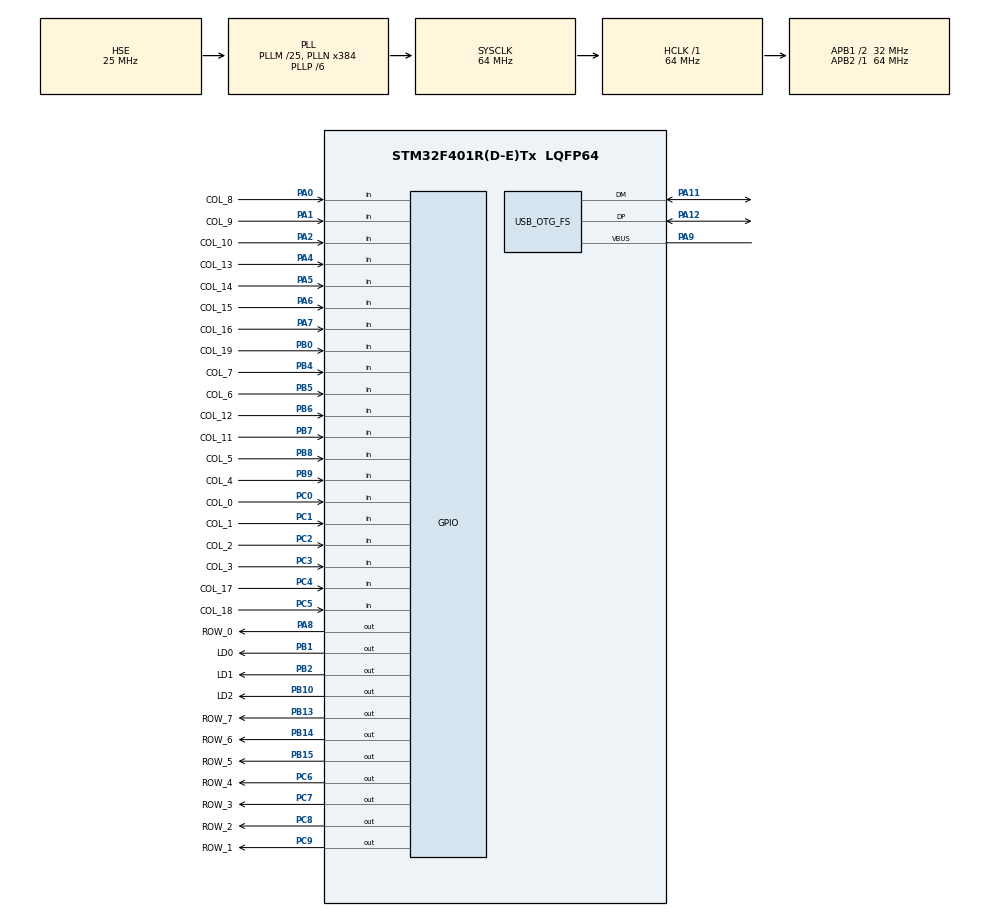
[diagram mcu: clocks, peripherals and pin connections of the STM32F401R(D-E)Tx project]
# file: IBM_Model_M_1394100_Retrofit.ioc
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FREERTOS.Tasks01=defaultTask,0,128,StartDefaultTask,Default,NULL,Dynamic,NULL,NULL
Mcu.Family=STM32F4
Mcu.Name=STM32F401R(D-E)Tx
Mcu.Package=LQFP64
NVIC.PriorityGroup=NVIC_PRIORITYGROUP_4
NVIC.TIM1_UP_TIM10_IRQn=true\:0\:0\:false\:false\:true\:false\:false\:true
NVIC.TimeBase=TIM1_UP_TIM10_IRQn
NVIC.TimeBaseIP=TIM10
PA0-WKUP.GPIO_Label=COL_8
PA0-WKUP.GPIO_Mode=GPIO_MODE_INPUT
PA0-WKUP.GPIO_PuPd=GPIO_PULLUP
PA0-WKUP.Signal=GPIO_Input
PA1.GPIO_Label=COL_9
PA1.GPIO_Mode=GPIO_MODE_INPUT
PA1.GPIO_PuPd=GPIO_PULLUP
PA1.Signal=GPIO_Input
PA11.Mode=Device_Only
PA11.Signal=USB_OTG_FS_DM
PA12.Mode=Device_Only
PA12.Signal=USB_OTG_FS_DP
PA13.Mode=Trace_Asynchronous_SW
PA13.Signal=SYS_JTMS-SWDIO
PA14.Mode=Trace_Asynchronous_SW
PA14.Signal=SYS_JTCK-SWCLK
PA2.GPIO_Label=COL_10
PA2.GPIO_Mode=GPIO_MODE_INPUT
PA2.GPIO_PuPd=GPIO_PULLUP
PA2.Signal=GPIO_Input
PA4.GPIO_Label=COL_13
PA4.GPIO_Mode=GPIO_MODE_INPUT
PA4.GPIO_PuPd=GPIO_PULLUP
PA4.Signal=GPIO_Input
PA5.GPIO_Label=COL_14
PA5.GPIO_Mode=GPIO_MODE_INPUT
PA5.GPIO_PuPd=GPIO_PULLUP
PA5.Signal=GPIO_Input
PA6.GPIO_Label=COL_15
PA6.GPIO_Mode=GPIO_MODE_INPUT
PA6.GPIO_PuPd=GPIO_PULLUP
PA6.Signal=GPIO_Input
PA7.GPIO_Label=COL_16
PA7.GPIO_Mode=GPIO_MODE_INPUT
PA7.GPIO_PuPd=GPIO_PULLUP
PA7.Signal=GPIO_Input
PA8.GPIO_Label=ROW_0
PA8.GPIO_ModeDefaultOutputPP=GPIO_MODE_OUTPUT_PP
PA8.GPIO_PuPd=GPIO_NOPULL
PA8.GPIO_Speed=GPIO_SPEED_FREQ_LOW
PA8.PinState=GPIO_PIN_SET
PA8.Signal=GPIO_Output
PA9.Mode=Activate_VBUS
PA9.Signal=USB_OTG_FS_VBUS
PB0.GPIO_Label=COL_19
PB0.GPIO_Mode=GPIO_MODE_INPUT
PB0.GPIO_PuPd=GPIO_PULLUP
PB0.Signal=GPIO_Input
PB1.GPIO_Label=LD0
PB1.Signal=GPIO_Output
PB10.GPIO_Label=LD2
PB10.Signal=GPIO_Output
PB13.GPIO_Label=ROW_7
PB13.GPIO_ModeDefaultOutputPP=GPIO_MODE_OUTPUT_PP
PB13.GPIO_PuPd=GPIO_NOPULL
PB13.GPIO_Speed=GPIO_SPEED_FREQ_LOW
PB13.PinState=GPIO_PIN_SET
PB13.Signal=GPIO_Output
PB14.GPIO_Label=ROW_6
PB14.GPIO_ModeDefaultOutputPP=GPIO_MODE_OUTPUT_PP
PB14.GPIO_PuPd=GPIO_NOPULL
PB14.GPIO_Speed=GPIO_SPEED_FREQ_LOW
PB14.PinState=GPIO_PIN_SET
PB14.Signal=GPIO_Output
PB15.GPIO_Label=ROW_5
PB15.GPIO_ModeDefaultOutputPP=GPIO_MODE_OUTPUT_PP
PB15.GPIO_PuPd=GPIO_NOPULL
PB15.GPIO_Speed=GPIO_SPEED_FREQ_LOW
PB15.PinState=GPIO_PIN_SET
PB15.Signal=GPIO_Output
PB2.GPIO_Label=LD1
PB2.Signal=GPIO_Output
PB3.Mode=Trace_Asynchronous_SW
PB3.Signal=SYS_JTDO-SWO
PB4.GPIO_Label=COL_7
PB4.GPIO_Mode=GPIO_MODE_INPUT
PB4.GPIO_PuPd=GPIO_PULLUP
PB4.Signal=GPIO_Input
PB5.GPIO_Label=COL_6
PB5.GPIO_Mode=GPIO_MODE_INPUT
PB5.GPIO_PuPd=GPIO_PULLUP
PB5.Signal=GPIO_Input
PB6.GPIO_Label=COL_12
PB6.GPIO_Mode=GPIO_MODE_INPUT
PB6.GPIO_PuPd=GPIO_PULLUP
PB6.Signal=GPIO_Input
PB7.GPIO_Label=COL_11
PB7.GPIO_Mode=GPIO_MODE_INPUT
PB7.GPIO_PuPd=GPIO_PULLUP
PB7.Signal=GPIO_Input
PB8.GPIO_Label=COL_5
PB8.GPIO_Mode=GPIO_MODE_INPUT
PB8.GPIO_PuPd=GPIO_PULLUP
PB8.Signal=GPIO_Input
PB9.GPIO_Label=COL_4
PB9.GPIO_Mode=GPIO_MODE_INPUT
PB9.GPIO_PuPd=GPIO_PULLUP
PB9.Signal=GPIO_Input
PC0.GPIO_Label=COL_0
PC0.GPIO_Mode=GPIO_MODE_INPUT
PC0.GPIO_PuPd=GPIO_PULLUP
PC0.Signal=GPIO_Input
PC1.GPIO_Label=COL_1
PC1.GPIO_Mode=GPIO_MODE_INPUT
PC1.GPIO_PuPd=GPIO_PULLUP
PC1.Signal=GPIO_Input
PC2.GPIO_Label=COL_2
PC2.GPIO_Mode=GPIO_MODE_INPUT
PC2.GPIO_PuPd=GPIO_PULLUP
PC2.Signal=GPIO_Input
PC3.GPIO_Label=COL_3
PC3.GPIO_Mode=GPIO_MODE_INPUT
PC3.GPIO_PuPd=GPIO_PULLUP
PC3.Signal=GPIO_Input
PC4.GPIO_Label=COL_17
PC4.GPIO_Mode=GPIO_MODE_INPUT
PC4.GPIO_PuPd=GPIO_PULLUP
PC4.Signal=GPIO_Input
PC5.GPIO_Label=COL_18
PC5.GPIO_Mode=GPIO_MODE_INPUT
PC5.GPIO_PuPd=GPIO_PULLUP
PC5.Signal=GPIO_Input
PC6.GPIO_Label=ROW_4
PC6.GPIO_ModeDefaultOutputPP=GPIO_MODE_OUTPUT_PP
PC6.GPIO_PuPd=GPIO_NOPULL
PC6.GPIO_Speed=GPIO_SPEED_FREQ_LOW
PC6.PinState=GPIO_PIN_SET
PC6.Signal=GPIO_Output
PC7.GPIO_Label=ROW_3
PC7.GPIO_ModeDefaultOutputPP=GPIO_MODE_OUTPUT_PP
PC7.GPIO_PuPd=GPIO_NOPULL
PC7.GPIO_Speed=GPIO_SPEED_FREQ_LOW
PC7.PinState=GPIO_PIN_SET
PC7.Signal=GPIO_Output
PC8.GPIO_Label=ROW_2
PC8.GPIO_ModeDefaultOutputPP=GPIO_MODE_OUTPUT_PP
PC8.GPIO_PuPd=GPIO_NOPULL
PC8.GPIO_Speed=GPIO_SPEED_FREQ_LOW
PC8.PinState=GPIO_PIN_SET
PC8.Signal=GPIO_Output
PC9.GPIO_Label=ROW_1
PC9.GPIO_ModeDefaultOutputPP=GPIO_MODE_OUTPUT_PP
PC9.GPIO_PuPd=GPIO_NOPULL
PC9.GPIO_Speed=GPIO_SPEED_FREQ_LOW
PC9.PinState=GPIO_PIN_SET
PC9.Signal=GPIO_Output
PH0\ -\ OSC_IN.Mode=HSE-External-Oscillator
PH0\ -\ OSC_IN.Signal=RCC_OSC_IN
PH1\ -\ OSC_OUT.Mode=HSE-External-Oscillator
PH1\ -\ OSC_OUT.Signal=RCC_OSC_OUT
ProjectManager.HeapSize=0x200
ProjectManager.StackSize=0x400
ProjectManager.TargetToolchain=STM32CubeIDE
RCC.48MHZClocksFreq_Value=48000000
RCC.AHBFreq_Value=64000000
RCC.APB1CLKDivider=RCC_HCLK_DIV2
RCC.APB1Freq_Value=32000000
RCC.APB1TimFreq_Value=64000000
RCC.APB2Freq_Value=64000000
RCC.APB2TimFreq_Value=64000000
RCC.CortexFreq_Value=64000000
RCC.HCLKFreq_Value=64000000
RCC.HSE_VALUE=25000000
RCC.HSI_VALUE=16000000
RCC.LSE_VALUE=32768
RCC.PLLM=25
RCC.PLLN=384
RCC.PLLP=RCC_PLLP_DIV6
RCC.PLLQ=8
RCC.SYSCLKFreq_VALUE=64000000
RCC.SYSCLKSource=RCC_SYSCLKSOURCE_PLLCLK
RCC.VCOOutputFreq_Value=384000000
USB_DEVICE.CLASS_NAME_FS=HID
USB_DEVICE.PRODUCT_STRING_HID_FS=IBM Model M 1394100
USB_DEVICE.VirtualMode-HID_FS=Hid
USB_DEVICE.VirtualModeFS=Hid_FS
USB_OTG_FS.VirtualMode=Device_Only
VP_FREERTOS_VS_CMSIS_V1.Mode=CMSIS_V1
VP_SYS_VS_tim10.Mode=TIM10
VP_USB_DEVICE_VS_USB_DEVICE_HID_FS.Mode=HID_FS
board=custom

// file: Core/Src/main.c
/* USER CODE BEGIN Header */
/**
 ******************************************************************************
 * @file           : main.c
 * @brief          : Main program body
 ******************************************************************************
 * @attention
 *
 * <h2><center>&copy; Copyright (c) 2020 STMicroelectronics.
 * All rights reserved.</center></h2>
 *
 * This software component is licensed by ST under BSD 3-Clause license,
 * the "License"; You may not use this file except in compliance with the
 * License. You may obtain a copy of the License at:
 *                        opensource.org/licenses/BSD-3-Clause
 *
 ******************************************************************************
 */
/* USER CODE END Header */

#include "main.h"
#include "cmsis_os.h"
#include "usb_device.h"
#include "gpio.h"

/* USER CODE BEGIN PV */
volatile _Bool os_running;
/* USER CODE END PV */

void SystemClock_Config(void);
void MX_FREERTOS_Init(void);

int main(void)
{
	/* USER CODE BEGIN 1 */
	os_running = 0;
	/* USER CODE END 1 */

	/* MCU Configuration--------------------------------------------------------*/

	/* Reset of all peripherals, Initializes the Flash interface and the Systick. */
	HAL_Init();

	/* Configure the system clock */
	SystemClock_Config();

	/* Initialize all configured peripherals */
	MX_GPIO_Init();

	/* Call init function for freertos objects (in freertos.c) */
	MX_FREERTOS_Init();

	/* Start scheduler */
	osKernelStart();

	/* We should never get here as control is now taken by the scheduler */

	/* Infinite loop */
	while (1)
	{

	}
}

void SystemClock_Config(void)
{
	RCC_OscInitTypeDef RCC_OscInitStruct = {0};
	RCC_ClkInitTypeDef RCC_ClkInitStruct = {0};

	/** Configure the main internal regulator output voltage
	 */
	__HAL_RCC_PWR_CLK_ENABLE();
	__HAL_PWR_VOLTAGESCALING_CONFIG(PWR_REGULATOR_VOLTAGE_SCALE2);
	/** Initializes the CPU, AHB and APB busses clocks
	 */
	RCC_OscInitStruct.OscillatorType = RCC_OSCILLATORTYPE_HSE;
	RCC_OscInitStruct.HSEState = RCC_HSE_ON;
	RCC_OscInitStruct.PLL.PLLState = RCC_PLL_ON;
	RCC_OscInitStruct.PLL.PLLSource = RCC_PLLSOURCE_HSE;
	RCC_OscInitStruct.PLL.PLLM = 25;
	RCC_OscInitStruct.PLL.PLLN = 384;
	RCC_OscInitStruct.PLL.PLLP = RCC_PLLP_DIV6;
	RCC_OscInitStruct.PLL.PLLQ = 8;
	if (HAL_RCC_OscConfig(&RCC_OscInitStruct) != HAL_OK)
	{
		Error_Handler();
	}
	/** Initializes the CPU, AHB and APB busses clocks
	 */
	RCC_ClkInitStruct.ClockType = RCC_CLOCKTYPE_HCLK|RCC_CLOCKTYPE_SYSCLK
			|RCC_CLOCKTYPE_PCLK1|RCC_CLOCKTYPE_PCLK2;
	RCC_ClkInitStruct.SYSCLKSource = RCC_SYSCLKSOURCE_PLLCLK;
	RCC_ClkInitStruct.AHBCLKDivider = RCC_SYSCLK_DIV1;
	RCC_ClkInitStruct.APB1CLKDivider = RCC_HCLK_DIV2;
	RCC_ClkInitStruct.APB2CLKDivider = RCC_HCLK_DIV1;

	if (HAL_RCC_ClockConfig(&RCC_ClkInitStruct, FLASH_LATENCY_2) != HAL_OK)
	{
		Error_Handler();
	}
}

void HAL_TIM_PeriodElapsedCallback(TIM_HandleTypeDef *htim)
{
	if (htim->Instance == TIM10) {
		HAL_IncTick();
	}
}

void Error_Handler(void)
{
}

/************************ (C) COPYRIGHT STMicroelectronics *****END OF FILE****/

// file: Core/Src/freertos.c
/* USER CODE BEGIN Header */
/**
 ******************************************************************************
 * File Name          : freertos.c
 * Description        : Code for freertos applications
 ******************************************************************************
 * @attention
 *
 * <h2><center>&copy; Copyright (c) 2019 STMicroelectronics.
 * All rights reserved.</center></h2>
 *
 * This software component is licensed by ST under Ultimate Liberty license
 * SLA0044, the "License"; You may not use this file except in compliance with
 * the License. You may obtain a copy of the License at:
 *                             www.st.com/SLA0044
 *
 ******************************************************************************
 */
/* USER CODE END Header */

#include "FreeRTOS.h"
#include "task.h"
#include "main.h"
#include "cmsis_os.h"

/* USER CODE BEGIN Includes */
#include "Keyboard/keyboard.h"
#include "UsbInterface/usb_if.h"
#include "Utilities/utils.h"
/* USER CODE END Includes */

osThreadId defaultTaskHandle;

void StartDefaultTask(void const * argument);

extern void MX_USB_DEVICE_Init(void);
void MX_FREERTOS_Init(void); /* (MISRA C 2004 rule 8.1) */

void MX_FREERTOS_Init(void) {

	/* Create the thread(s) */
	/* definition and creation of defaultTask */
	osThreadDef(defaultTask, StartDefaultTask, osPriorityNormal, 0, 128);
	defaultTaskHandle = osThreadCreate(osThread(defaultTask), NULL);

	/* USER CODE BEGIN RTOS_THREADS */
	/* add threads, ... */
	usbifInit();
	keyboardInit();
	utilsInit();
	/* USER CODE END RTOS_THREADS */

}

void StartDefaultTask(void const * argument)
{
	/* init code for USB_DEVICE */
	MX_USB_DEVICE_Init();

	/* USER CODE BEGIN StartDefaultTask */
	os_running = 1;
	/* Infinite loop */
	for(;;)
	{
		osDelay(1);
	}
	/* USER CODE END StartDefaultTask */
}

/************************ (C) COPYRIGHT STMicroelectronics *****END OF FILE****/
